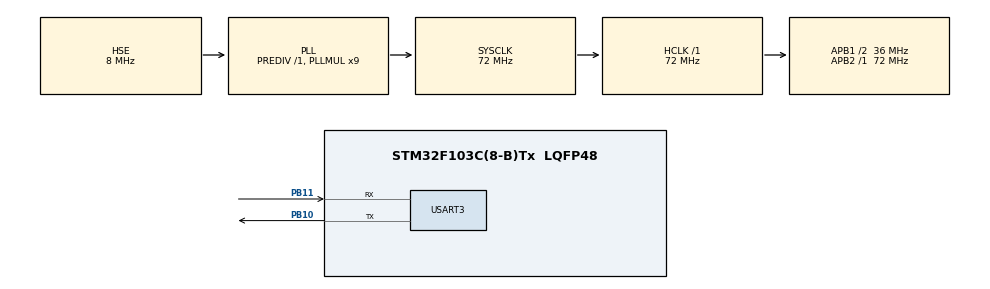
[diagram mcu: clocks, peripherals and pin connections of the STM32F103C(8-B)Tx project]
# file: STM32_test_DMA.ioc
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Dma.MEMTOMEM.1.Direction=DMA_MEMORY_TO_MEMORY
Dma.MEMTOMEM.1.Instance=DMA1_Channel1
Dma.MEMTOMEM.1.MemDataAlignment=DMA_MDATAALIGN_BYTE
Dma.MEMTOMEM.1.MemInc=DMA_MINC_ENABLE
Dma.MEMTOMEM.1.Mode=DMA_NORMAL
Dma.MEMTOMEM.1.PeriphDataAlignment=DMA_PDATAALIGN_BYTE
Dma.MEMTOMEM.1.PeriphInc=DMA_PINC_DISABLE
Dma.MEMTOMEM.1.Priority=DMA_PRIORITY_LOW
Dma.Request0=USART3_RX
Dma.Request1=MEMTOMEM
Dma.USART3_RX.0.Direction=DMA_PERIPH_TO_MEMORY
Dma.USART3_RX.0.Instance=DMA1_Channel3
Dma.USART3_RX.0.MemDataAlignment=DMA_MDATAALIGN_BYTE
Dma.USART3_RX.0.MemInc=DMA_MINC_ENABLE
Dma.USART3_RX.0.Mode=DMA_NORMAL
Dma.USART3_RX.0.PeriphDataAlignment=DMA_PDATAALIGN_BYTE
Dma.USART3_RX.0.PeriphInc=DMA_PINC_DISABLE
Dma.USART3_RX.0.Priority=DMA_PRIORITY_HIGH
Mcu.Family=STM32F1
Mcu.Name=STM32F103C(8-B)Tx
Mcu.Package=LQFP48
NVIC.DMA1_Channel3_IRQn=true\:2\:1\:true\:false\:true\:false\:true\:true
NVIC.PriorityGroup=NVIC_PRIORITYGROUP_2
NVIC.USART3_IRQn=true\:3\:1\:true\:false\:true\:true\:true\:true
PA13.Mode=Serial_Wire
PA13.Signal=SYS_JTMS-SWDIO
PA14.Mode=Serial_Wire
PA14.Signal=SYS_JTCK-SWCLK
PB10.Mode=Asynchronous
PB10.Signal=USART3_TX
PB11.GPIO_PuPd=GPIO_PULLUP
PB11.Mode=Asynchronous
PB11.Signal=USART3_RX
PD0-OSC_IN.Mode=HSE-External-Oscillator
PD0-OSC_IN.Signal=RCC_OSC_IN
PD1-OSC_OUT.Mode=HSE-External-Oscillator
PD1-OSC_OUT.Signal=RCC_OSC_OUT
ProjectManager.HeapSize=0x200
ProjectManager.StackSize=0x400
ProjectManager.TargetToolchain=MDK-ARM V5.32
RCC.AHBFreq_Value=72000000
RCC.APB1CLKDivider=RCC_HCLK_DIV2
RCC.APB1Freq_Value=36000000
RCC.APB1TimFreq_Value=72000000
RCC.APB2Freq_Value=72000000
RCC.APB2TimFreq_Value=72000000
RCC.HCLKFreq_Value=72000000
RCC.PLLMUL=RCC_PLL_MUL9
RCC.PLLSourceVirtual=RCC_PLLSOURCE_HSE
RCC.SYSCLKFreq_VALUE=72000000
RCC.SYSCLKSource=RCC_SYSCLKSOURCE_PLLCLK
RCC.USBFreq_Value=72000000
USART3.VirtualMode=VM_ASYNC
board=custom

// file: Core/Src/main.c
/* USER CODE BEGIN Header */
/**
  ******************************************************************************
  * @file           : main.c
  * @brief          : Main program body
  ******************************************************************************
  * @attention
  *
  * Copyright (c) 2022 STMicroelectronics.
  * All rights reserved.
  *
  * This software is licensed under terms that can be found in the LICENSE file
  * in the root directory of this software component.
  * If no LICENSE file comes with this software, it is provided AS-IS.
  *
  ******************************************************************************
  */
/* USER CODE END Header */
#include "main.h"
#include "dma.h"
#include "usart.h"
#include "gpio.h"

/* USER CODE BEGIN Includes */
#include "stdio.h"
#define RECV_SIZE 255
#define AHEAD 'F'
#define LEFT  'L'
#define RIGHT 'R'
#define BACK  'B'
typedef struct
{
	int speed;
	char direct;
}Order_Struct;
Order_Struct rx_Order;
/* USER CODE END Includes */

/* USER CODE BEGIN PTD */
void HandleData(uint8_t *data,int length)
{
	/*
	1、PWM速度数据：[-1000，1000]
	2、方向指令：
		AHEAD -> 前进
		LEFT  -> 左转
		RIGHT -> 右转
		BACK  -> 后退
	*/
	int speed_set = 0;
	// 判断数据是否为速度指令
	// 是否为负数
	if(data[0] == '-' && length <= 5)
	{
		speed_set = 0;
		for(int i = 1;i < length;i++)
			speed_set = speed_set * 10 + data[i] - '0';
		rx_Order.speed = -speed_set;
	}
	// 是否为正数
	else if(data[0] >= '0' && data[0] <= '9' && length <= 4)
	{
		speed_set = 0;
		for(int i = 0;i < length;i++)
			speed_set = speed_set * 10 + data[i] - '0';
		rx_Order.speed = speed_set;
	}
	// 判断是否为方向指令
	else if(data[0] >= 'A' && data[0] <= 'Z' && length == 1)
	{
		switch(data[0])
		{
			case AHEAD:
			case LEFT:
			case RIGHT:
			case BACK:
				rx_Order.direct = data[0];
				break;
			default:
				printf("Error message");
				break;
		}
	}
}
/* USER CODE END PTD */

void SystemClock_Config(void);

/* USER CODE BEGIN 0 */
uint8_t usart3_recv[RECV_SIZE];
extern int data_length;
/* USER CODE END 0 */

int main(void)
{

  /* MCU Configuration--------------------------------------------------------*/

  /* Reset of all peripherals, Initializes the Flash interface and the Systick. */
  HAL_Init();

  /* Configure the system clock */
  SystemClock_Config();

  /* Initialize all configured peripherals */
  MX_GPIO_Init();
  MX_DMA_Init();
  MX_USART3_UART_Init();
  /* USER CODE BEGIN 2 */
  //使能接收中断和空闲中断并打开DMA接收
  __HAL_UART_ENABLE_IT(&huart3, UART_IT_RXNE);
  __HAL_UART_ENABLE_IT(&huart3, UART_IT_IDLE);
  __HAL_UART_CLEAR_IDLEFLAG(&huart3);
    HAL_UART_Receive_DMA(&huart3, usart3_recv, RECV_SIZE);
  /* USER CODE END 2 */

  /* Infinite loop */
  while (1)
  {

    /* USER CODE BEGIN 3 */
	  HandleData(usart3_recv,data_length);
	  printf("speed:%d  direct:%c\r\n",rx_Order.speed,rx_Order.direct);
	  HAL_Delay(1000);
  }
  /* USER CODE END 3 */
}

void SystemClock_Config(void)
{
  RCC_OscInitTypeDef RCC_OscInitStruct = {0};
  RCC_ClkInitTypeDef RCC_ClkInitStruct = {0};

  /** Initializes the RCC Oscillators according to the specified parameters
  * in the RCC_OscInitTypeDef structure.
  */
  RCC_OscInitStruct.OscillatorType = RCC_OSCILLATORTYPE_HSE;
  RCC_OscInitStruct.HSEState = RCC_HSE_ON;
  RCC_OscInitStruct.HSEPredivValue = RCC_HSE_PREDIV_DIV1;
  RCC_OscInitStruct.HSIState = RCC_HSI_ON;
  RCC_OscInitStruct.PLL.PLLState = RCC_PLL_ON;
  RCC_OscInitStruct.PLL.PLLSource = RCC_PLLSOURCE_HSE;
  RCC_OscInitStruct.PLL.PLLMUL = RCC_PLL_MUL9;
  if (HAL_RCC_OscConfig(&RCC_OscInitStruct) != HAL_OK)
  {
    Error_Handler();
  }

  /** Initializes the CPU, AHB and APB buses clocks
  */
  RCC_ClkInitStruct.ClockType = RCC_CLOCKTYPE_HCLK|RCC_CLOCKTYPE_SYSCLK
                              |RCC_CLOCKTYPE_PCLK1|RCC_CLOCKTYPE_PCLK2;
  RCC_ClkInitStruct.SYSCLKSource = RCC_SYSCLKSOURCE_PLLCLK;
  RCC_ClkInitStruct.AHBCLKDivider = RCC_SYSCLK_DIV1;
  RCC_ClkInitStruct.APB1CLKDivider = RCC_HCLK_DIV2;
  RCC_ClkInitStruct.APB2CLKDivider = RCC_HCLK_DIV1;

  if (HAL_RCC_ClockConfig(&RCC_ClkInitStruct, FLASH_LATENCY_2) != HAL_OK)
  {
    Error_Handler();
  }
}

void Error_Handler(void)
{
  __disable_irq();
  while (1)
  {
  }
}
